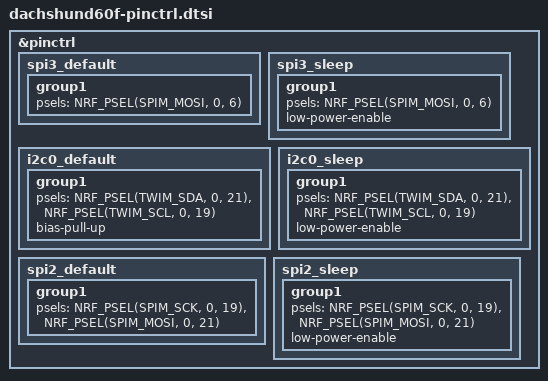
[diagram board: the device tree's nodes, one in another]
/* Pin muxing for the Dachshund60F. Pins come from board.json. */

&pinctrl {
	/* SK6812 data: SPIM MOSI only, clocked at 4 MHz by the ws2812-spi driver. */
	spi3_default: spi3_default {
		group1 {
			psels = <NRF_PSEL(SPIM_MOSI, 0, 6)>;
		};
	};

	spi3_sleep: spi3_sleep {
		group1 {
			psels = <NRF_PSEL(SPIM_MOSI, 0, 6)>;
			low-power-enable;
		};
	};

	/* Display header J4, I2C OLED: SDA on DIN (J4-3), SCL on CLK (J4-4). */
	i2c0_default: i2c0_default {
		group1 {
			psels = <NRF_PSEL(TWIM_SDA, 0, 21)>,
				<NRF_PSEL(TWIM_SCL, 0, 19)>;
			bias-pull-up;
		};
	};

	i2c0_sleep: i2c0_sleep {
		group1 {
			psels = <NRF_PSEL(TWIM_SDA, 0, 21)>,
				<NRF_PSEL(TWIM_SCL, 0, 19)>;
			low-power-enable;
		};
	};

	/* Display header J4, SPI e-paper: MOSI on DIN (J4-3), SCK on CLK (J4-4). */
	spi2_default: spi2_default {
		group1 {
			psels = <NRF_PSEL(SPIM_SCK, 0, 19)>,
				<NRF_PSEL(SPIM_MOSI, 0, 21)>;
		};
	};

	spi2_sleep: spi2_sleep {
		group1 {
			psels = <NRF_PSEL(SPIM_SCK, 0, 19)>,
				<NRF_PSEL(SPIM_MOSI, 0, 21)>;
			low-power-enable;
		};
	};
};
